VERSION ""

NS_ :

BS_:

BU_: XXX

BO_ 528 NEW_MSG_1: 8 XXX
 SG_ NEW_SIGNAL_1 : 15|16@0- (1,0) [0|65535] "" XXX
 SG_ NEW_SIGNAL_2 : 7|8@0+ (1,0) [0|255] "" XXX

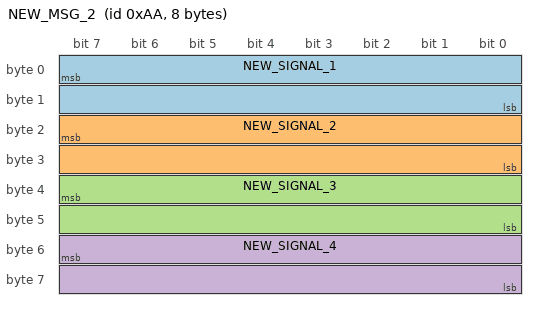
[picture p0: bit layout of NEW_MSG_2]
BO_ 170 NEW_MSG_2: 8 XXX
 SG_ NEW_SIGNAL_1 : 7|16@0+ (1,-6767) [0|65535] "" XXX
 SG_ NEW_SIGNAL_2 : 23|16@0+ (1,-6767) [0|65535] "" XXX
 SG_ NEW_SIGNAL_3 : 39|16@0+ (1,-6767) [0|65535] "" XXX
 SG_ NEW_SIGNAL_4 : 55|16@0+ (1,-6767) [0|65535] "" XXX
